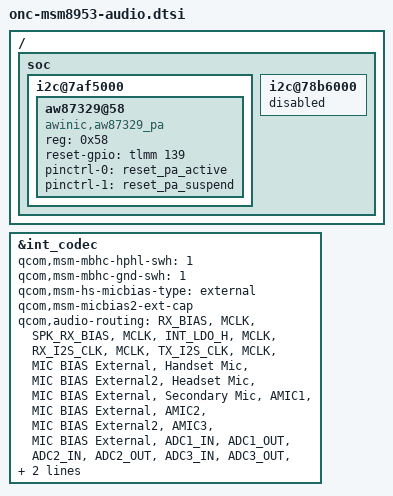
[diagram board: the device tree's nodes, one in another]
/*
 * Copyright (c) 2015-2019, The Linux Foundation. All rights reserved.
 * Copyright (C) 2020-2024 XiaoMi, Inc.
 *
 * This program is free software; you can redistribute it and/or modify
 * it under the terms of the GNU General Public License version 2 and
 * only version 2 as published by the Free Software Foundation.
 */

/ {
	soc {
		i2c@7af5000 { /* BLSP2 QUP1 */
			status = "okay";
			aw87329@58 {
				status = "okay";
				compatible = "awinic,aw87329_pa";
				reg = <0x58>;
				reset-gpio = <&tlmm 139 0>;
				pinctrl-names = "reset_pa_act", "reset_pa_sus";
				pinctrl-0 = <&reset_pa_active>;
				pinctrl-1 = <&reset_pa_suspend>;
			};
		};

		i2c@78b6000 { /* BLSP1 QUP2 */
			status = "disabled";
		};
	};
};

&int_codec {
	qcom,msm-mbhc-hphl-swh = <1>;
	qcom,msm-mbhc-gnd-swh = <1>;
	qcom,msm-hs-micbias-type = "external";
	qcom,msm-micbias2-ext-cap;

	/delete-property/ asoc-wsa-codec-names;
	/delete-property/ asoc-wsa-codec-prefixes;
	/delete-property/ msm-vdd-wsa-switch-supply;
	/delete-property/ qcom,msm-vdd-wsa-switch-voltage;
	/delete-property/ qcom,msm-vdd-wsa-switch-current;
	/delete-property/ qcom,cdc-us-euro-gpios;
	/delete-property/ qcom,cdc-us-eu-gpios;
	/delete-property/ qcom,afe-rxtx-lb;

	qcom,audio-routing =
			"RX_BIAS", "MCLK",
			"SPK_RX_BIAS", "MCLK",
			"INT_LDO_H", "MCLK",
			"RX_I2S_CLK", "MCLK",
			"TX_I2S_CLK", "MCLK",
			"MIC BIAS External", "Handset Mic",
			"MIC BIAS External2", "Headset Mic",
			"MIC BIAS External", "Secondary Mic",
			"AMIC1", "MIC BIAS External",
			"AMIC2", "MIC BIAS External2",
			"AMIC3", "MIC BIAS External",
			"ADC1_IN", "ADC1_OUT",
			"ADC2_IN", "ADC2_OUT",
			"ADC3_IN", "ADC3_OUT",
			"PDM_IN_RX1", "PDM_OUT_RX1",
			"PDM_IN_RX2", "PDM_OUT_RX2",
			"PDM_IN_RX3", "PDM_OUT_RX3";
};
